# STM32F767 register map
File version: 1.6
CPU: CM7 r0p1, little endian, MPU, FPU, 4 interrupt priority bits
Registers are 32-bit, read-write, reset 0x0 unless marked. A register's access mark holds for its fields unless they carry their own. Offsets are from the block's base; [hi:lo] are bit positions; {n}, {i} and the like mark numbered series.

## LPTIM1 — Low power timer
Base 0x40002400
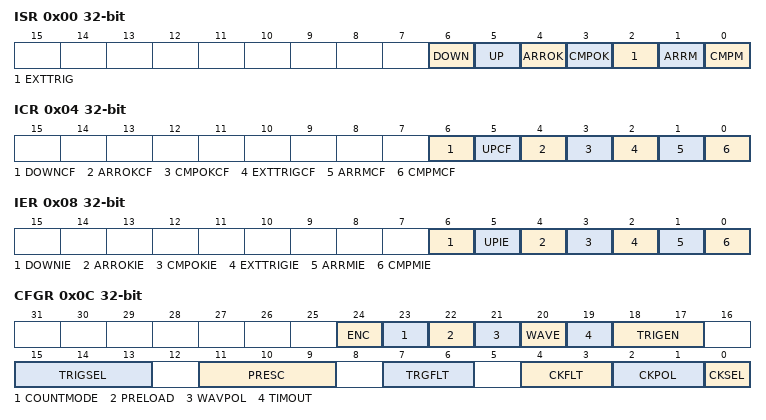
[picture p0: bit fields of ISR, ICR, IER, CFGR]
0x00 ISR ro — Interrupt and Status Register
  [6] DOWN — Counter direction change up to down
  [5] UP — Counter direction change down to up
  [4] ARROK — Autoreload register update OK
  [3] CMPOK — Compare register update OK
  [2] EXTTRIG — External trigger edge event
  [1] ARRM — Autoreload match
  [0] CMPM — Compare match
0x04 ICR wo — Interrupt Clear Register
  [6] DOWNCF — Direction change to down Clear Flag
  [5] UPCF — Direction change to UP Clear Flag
  [4] ARROKCF — Autoreload register update OK Clear Flag
  [3] CMPOKCF — Compare register update OK Clear Flag
  [2] EXTTRIGCF — External trigger valid edge Clear Flag
  [1] ARRMCF — Autoreload match Clear Flag
  [0] CMPMCF — compare match Clear Flag
0x08 IER — Interrupt Enable Register
  [6] DOWNIE — Direction change to down Interrupt Enable
  [5] UPIE — Direction change to UP Interrupt Enable
  [4] ARROKIE — Autoreload register update OK Interrupt Enable
  [3] CMPOKIE — Compare register update OK Interrupt Enable
  [2] EXTTRIGIE — External trigger valid edge Interrupt Enable
  [1] ARRMIE — Autoreload match Interrupt Enable
  [0] CMPMIE — Compare match Interrupt Enable
0x0C CFGR — Configuration Register
  [24] ENC — Encoder mode enable
  [23] COUNTMODE — counter mode enabled
  [22] PRELOAD — Registers update mode
  [21] WAVPOL — Waveform shape polarity
  [20] WAVE — Waveform shape
  [19] TIMOUT — Timeout enable
  [18:17] TRIGEN — Trigger enable and polarity
  [15:13] TRIGSEL — Trigger selector
  [11:9] PRESC — Clock prescaler
  [7:6] TRGFLT — Configurable digital filter for trigger
  [4:3] CKFLT — Configurable digital filter for external clock
  [2:1] CKPOL — Clock Polarity
  [0] CKSEL — Clock selector
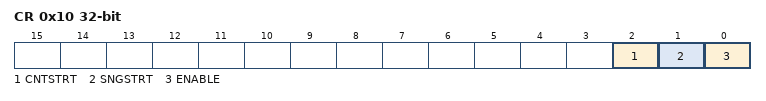
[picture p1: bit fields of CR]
0x10 CR — Control Register
  [2] CNTSTRT — Timer start in continuous mode
  [1] SNGSTRT — LPTIM start in single mode
  [0] ENABLE — LPTIM Enable
0x14 CMP — Compare Register
  [15:0] CMP — Compare value
0x18 ARR reset 0x1 — Autoreload Register
  [15:0] ARR — Auto reload value
0x1C CNT ro — Counter Register
  [15:0] CNT — Counter value

## MDIOS — Management data input/output slave
Base 0x40017800
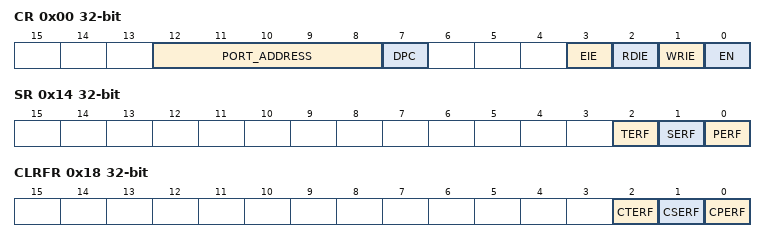
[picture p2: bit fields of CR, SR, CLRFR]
0x00 CR — MDIOS configuration register
  [12:8] PORT_ADDRESS — Slaves's address
  [7] DPC — Disable Preamble Check
  [3] EIE — Error interrupt enable
  [2] RDIE — Register Read Interrupt Enable
  [1] WRIE — Register write interrupt enable
  [0] EN — Peripheral enable
0x04 WRFR ro — MDIOS write flag register
  [31:0] WRF — Write flags for MDIO registers 0 to 31
0x08 CWRFR — MDIOS clear write flag register
  [31:0] CWRF — Clear the write flag
0x0C RDFR ro — MDIOS read flag register
  [31:0] RDF — Read flags for MDIO registers 0 to 31
0x10 CRDFR — MDIOS clear read flag register
  [31:0] CRDF — Clear the read flag
0x14 SR ro — MDIOS status register
  [2] TERF — Turnaround error flag
  [1] SERF — Start error flag
  [0] PERF — Preamble error flag
0x18 CLRFR — MDIOS clear flag register
  [2] CTERF — Clear the turnaround error flag
  [1] CSERF — Clear the start error flag
  [0] CPERF — Clear the preamble error flag
{0x1C+4i} DINR{i} (i=0..31) ro — MDIOS input data register {i}
  [15:0] DIN — Input data received from MDIO Master during write frames
{0x9C+4i} DOUTR{i} (i=0..31) — MDIOS output data register {i}
  [15:0] DOUT — Output data sent to MDIO Master during read frames

## JPEG — JPEG codec
Base 0x50051000
0x00 CONFR0 wo — JPEG codec configuration register 0
  [0] START
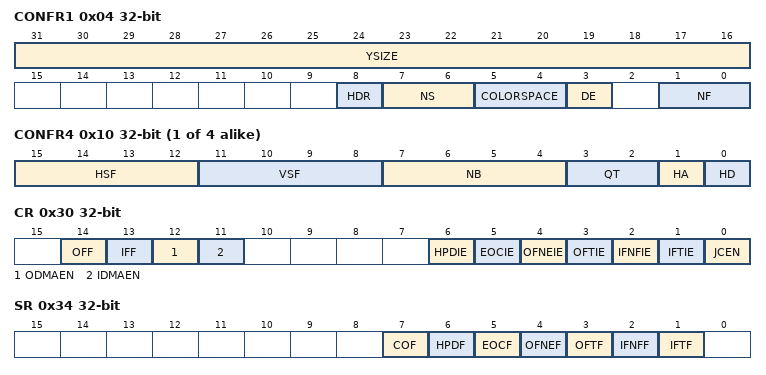
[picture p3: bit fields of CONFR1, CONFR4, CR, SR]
0x04 CONFR1 — JPEG codec configuration register 1
  [31:16] YSIZE
  [8] HDR — Header Processing
  [7:6] NS — Number of components for Scan
  [5:4] COLORSPACE
  [3] DE — Decoding Enable
  [1:0] NF — Number of color components
0x08 CONFR2 — JPEG codec configuration register 2
  [25:0] NMCU — Number of MCU
0x0C CONFR3 — JPEG codec configuration register 3
  [31:16] XSIZE
{0x0+4i} CONFR{i} (i=4..7) — JPEG codec configuration register {i}
  [15:12] HSF — Horizontal Sampling Factor
  [11:8] VSF — Vertical Sampling Factor
  [7:4] NB — Number of Block
  [3:2] QT — Quantization Table
  [1] HA — Huffman AC
  [0] HD — Huffman DC
0x30 CR access per field — JPEG control register
  [14] OFF ro — Output FIFO Flush
  [13] IFF ro — Input FIFO Flush
  [12] ODMAEN rw — Output DMA Enable
  [11] IDMAEN rw — Input DMA Enable
  [6] HPDIE rw — Header Parsing Done Interrupt Enable
  [5] EOCIE rw — End of Conversion Interrupt Enable
  [4] OFNEIE rw — Output FIFO Not Empty Interrupt Enable
  [3] OFTIE rw — Output FIFO Threshold Interrupt Enable
  [2] IFNFIE rw — Input FIFO Not Full Interrupt Enable
  [1] IFTIE rw — Input FIFO Threshold Interrupt Enable
  [0] JCEN rw — JPEG Core Enable
0x34 SR ro — JPEG status register
  [7] COF — Codec Operation Flag
  [6] HPDF — Header Parsing Done Flag
  [5] EOCF — End of Conversion Flag
  [4] OFNEF — Output FIFO Not Empty Flag
  [3] OFTF — Output FIFO Threshold Flag
  [2] IFNFF — Input FIFO Not Full Flag
  [1] IFTF — Input FIFO Threshold Flag
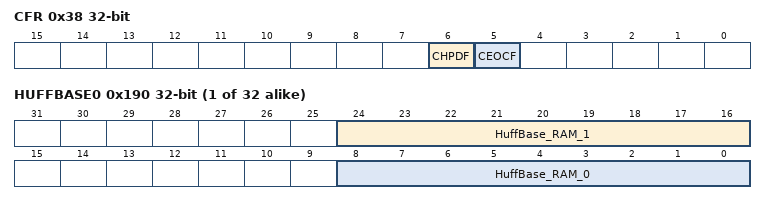
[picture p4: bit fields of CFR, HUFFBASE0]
0x38 CFR wo — JPEG clear flag register
  [6] CHPDF — Clear Header Parsing Done Flag
  [5] CEOCF — Clear End of Conversion Flag
0x40 DIR wo — JPEG data input register
  [31:0] DATAIN — Data Input FIFO
0x44 DOR ro — JPEG data output register
  [31:0] DATAOUT — Data Output FIFO
{0x50+4i} QMEM0{i} (i=0..15) — JPEG quantization tables
  [31:0] QMem_RAM
{0x90+4i} QMEM1{i} (i=0..15) — JPEG quantization tables
  [31:0] QMem_RAM
{0xD0+4i} QMEM2{i} (i=0..15) — JPEG quantization tables
  [31:0] QMem_RAM
{0x110+4i} QMEM3{i} (i=0..15) — JPEG quantization tables
  [31:0] QMem_RAM
{0x150+4i} HUFFMIN{i} (i=0..15) — JPEG HuffMin tables
  [31:0] HuffMin_RAM
{0x190+4i} HUFFBASE{i} (i=0..31) — JPEG HuffSymb tables
  [24:16] HuffBase_RAM_1 — HuffBase RAM
  [8:0] HuffBase_RAM_0 — HuffBase RAM
{0x210+4i} HUFFSYMB{i} (i=0..83) — JPEG HUFFSYMB tables
  [31:0] HuffSymb_RAM — DHTSymb RAM
0x360 DHTMEM{x} (x=0,2,3,4,5,6,7,8,9,10,11,12,13,14,15,16,17,18,19,20,21,22,23,24,25,26,27,28,29,30,31,32,33,34,35,36,37,38,39,40,41,42,43,44,45,46,47,48,49,50,51,52,53,54,55,56,57,58,59,60,61,62,63,64,65,66,67,68,69,70,71,72,73,74,75,76,77,78,79,80,81,82,83,84,85,86,87,88,89,90,91,92,93,94,95,96,97,98,99,100,101,102,103; step 0x4) — JPEG DHTMem tables
  [31:0] DHTMem_RAM
{0x500+4i} HUFFENC_AC0{i} (i=0..87) — JPEG encoder, AC Huffman table 0
  [31:0] DHTMem_RAM
{0x660+4i} HUFFENC_AC1{i} (i=0..87) — JPEG encoder, AC Huffman table 1
  [31:0] DHTMem_RAM
{0x7C0+4i} HUFFENC_DC0{i} (i=0..7) — JPEG encoder, DC Huffman table 0
  [31:0] DHTMem_RAM
{0x7E0+4i} HUFFENC_DC1{i} (i=0..7) — JPEG encoder, DC Huffman table 1
  [31:0] DHTMem_RAM
